# RA register map
Vendor: Renesas; Series: All Chips; File version: x.xx
Registers are 32-bit, read-write, reset 0x0 unless marked. A register's access mark holds for its fields unless they carry their own. Offsets are from the block's base; [hi:lo] are bit positions; lines under a group give offsets from that group; {n}, {i} and the like mark numbered series; 'fields as' and 'values as' point back to an identical list.

## R_ETHERC_EPTPC_COMMON — Ethernet PTP Controller Common
Base 0x40065000
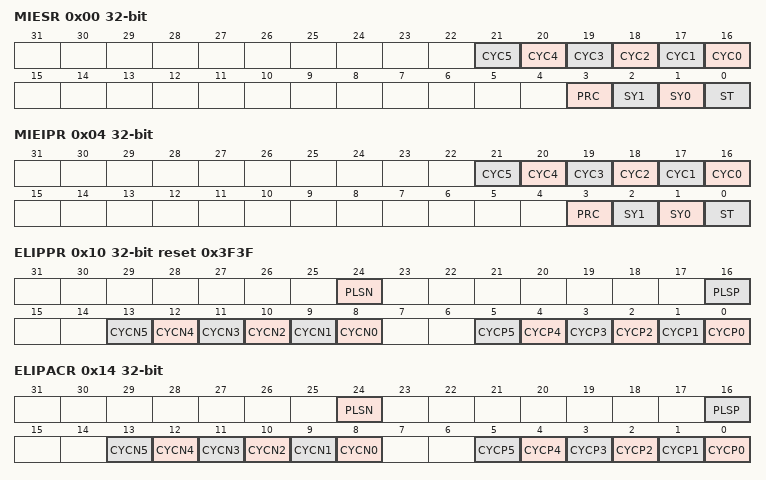
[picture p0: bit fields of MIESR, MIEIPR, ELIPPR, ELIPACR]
0x00 MIESR — MINT Interrupt Source Status Register
  [n+16] CYC{n} write-1-clears read-modifies (n=0..5) — Pulse Output Timer {n} Rising Edge Detection Flag
    0=A rising edge in the periodic pulse signal from pulse output timer {n} is not detected; 1=A rising edge in the periodic pulse signal from pulse output timer {n} is detected
  [3] PRC ro — PRC-TC Status Flag
    0=No change in the state of the PRC-TC module; 1=A change in the state of the PRC-TC module
  [2] SY1 ro — SYNFP1 Status Flag
    0=No change in the state of the SYNFP1 module; 1=A change in the state of the SYNFP1 module
  [1] SY0 ro — SYNFP0 Status Flag
    0=No change in the state of the SYNFP0 module; 1=A change in the state of the SYNFP0 module
  [0] ST ro — STCA Status Flag
    0=No change in the state of the STCA module; 1=A change in the state of the STCA module
0x04 MIEIPR — MINT Interrupt Request Permission Register
  [n+16] CYC{n} (n=0..5) — Pulse Output Timer {n} Rising Edge Detection Interrupt Request Permission
    0=Prohibits the generation of MINT interrupt requests in response to detection of a rising edge of pulse output timer {n}; 1=Permits the generation of MINT interrupt requests in response to detection of a rising edge of pulse output timer {n}
  [3] PRC — PRC-TC Status Interrupt Request Permission
    0=Prohibits the generation of MINT interrupt requests by the PRC-TC status flag; 1=Permits the generation of MINT interrupt requests by the PRCTC status flag
  [2] SY1 — SYNFP1 Status Interrupt Request Permission
    0=Prohibits the generation of MINT interrupt requests by the SYNFP1 status flag; 1=Permits the generation of MINT interrupt requests by the SYNFP1 status flag
  [1] SY0 — SYNFP0 Status Interrupt Request Permission
    0=Prohibits the generation of MINT interrupt requests by the SYNFP0 status flag; 1=Permits the generation of MINT interrupt requests by the SYNFP0 status flag
  [0] ST — STCA Status Interrupt Request Permission
    0=Prohibits the generation of MINT interrupt requests by the STCA status flag; 1=Permits the generation of MINT interrupt requests by the STCA status flag
0x10 ELIPPR reset 0x3F3F — ELC Output/ETHER_IPLS Interrupt Request Permission Register
  [24] PLSN — Pulse Output Timer Falling Edge Detection IPLS Interrupt Request Permission
    0=Prohibits IPLS interrupt requests due to falling edges of signals from the selected pulse output timer; 1=Permits IPLS interrupt requests due to falling edges of signals from the selected pulse output timer
  [16] PLSP — Pulse Output Timer Rising Edge Detection IPLS Interrupt Request Permission
    0=Prohibits IPLS interrupt requests due to rising edges of signals from the selected pulse output timer; 1=Permits IPLS interrupt requests due to rising edges of signals from the selected pulse output timer
  [n+8] CYCN{n} (n=0..5) — Pulse Output Timer {n} Falling Edge Detection Event Output Enable
    0=Falling edges of the signal from pulse output timer {n} are not conveyed to the ELC as event signals; 1=Falling edges of the signal from pulse output timer {n} are conveyed to the ELC as event signals
  [n] CYCP{n} (n=0..5) — Pulse Output Timer {n} Rising Edge Detection Event Output Enable
    0=Rising edges of the signal from pulse output timer {n} are not conveyed to the ELC as event signals; 1=Rising edges of the signal from pulse output timer {n} are conveyed to the ELC as event signals
0x14 ELIPACR — ELC Output/IPLS Interrupt Permission Automatic Clearing Register
  [24] PLSN — ELIPPR.PLSN Bit Automatic Clearing
    0=Disables automatic clearing of the enable bit for IPLS interrupt requests in response to detection of rising edges of the pulse output timer; 1=Enables automatic clearing of the enable bit for IPLS interrupt requests in response to detection of rising edges of the pulse output timer
  [16] PLSP — ELIPPR.PLSP Bit Automatic Clearing
    values as PLSN
  [n+8] CYCN{n} (n=0..5) — ELIPPR.CYCN{n} Bit Automatic Clearing
    0=Disables automatic clearing of the enable bit for the output of falling edges of pulse output timer {n}; 1=Enables automatic clearing of the enable bit for the output of falling edges of pulse output timer {n}
  [n] CYCP{n} (n=0..5) — ELIPPR.CYCP{n} Bit Automatic Clearing
    0=Disables automatic clearing of the enable bit for the output of rising edges of pulse output timer {n}; 1=Enables automatic clearing of the enable bit for the output of rising edges of pulse output timer {n}
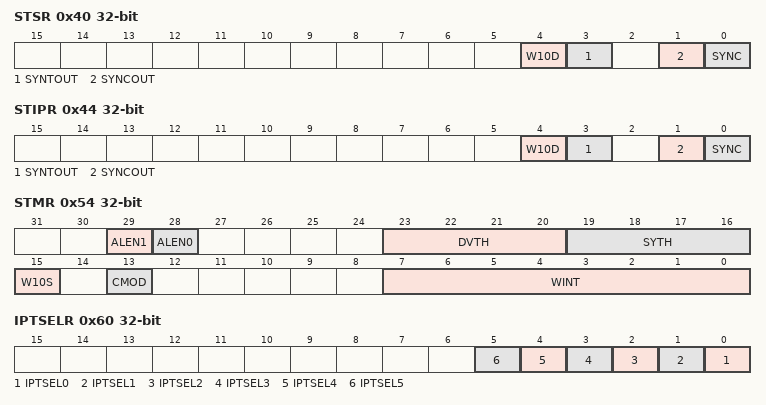
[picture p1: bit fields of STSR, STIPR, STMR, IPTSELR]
0x40 STSR — STCA Status Register
  [4] W10D write-1-clears — Worst 10 Acquisition Completion Flag
    0=Ten worst values not acquired yet; 1=Ten worst values acquired
  [3] SYNTOUT write-1-clears — Sync Message Reception Timeout Detection Flag
    0=Sync message reception timeout not detected; 1=Sync message reception timeout detected
  [1] SYNCOUT write-1-clears — Synchronization Loss Detection Flag
    0=Loss of synchronization not detected; 1=Loss of synchronization detected
  [0] SYNC write-1-clears — Synchronized State Detection Flag
    0=Synchronization not detected; 1=Synchronization detected
0x44 STIPR — STCA Status Notification Permission Register
  [4] W10D — W10D Status Notification Enable
    0=Disable notification of the STSR.W10D state; 1=Enable notification of the STSR.W10D state
  [3] SYNTOUT — SYNTOUT Status Notification Enable
    0=Disable notification of the STSR.SYNTOUT state; 1=Enable notification of the STSR.SYNTOUT state
  [1] SYNCOUT — SYNCOUT Status Notification Enable
    0=Disable notification of the STSR.SYNCOUT state; 1=Enable notification of the STSR.SYNCOUT state
  [0] SYNC — SYNC Status Notification Enable
    0=Disable notification of the STSR.SYNC state; 1=Enable notification of the STSR.SYNC state
0x50 STCFR — STCA Clock Frequency Setting Register
  [1:0] STCF — STCA Clock Frequency
    0=20MHz; 1=25MHz; 2=50MHz; 3=100 MHz
0x54 STMR — STCA Operating Mode Register
  [29] ALEN1 — Alarm Detection Enable 1
    0=The STSR.SYNTOUT flag is not set to 1 on detection of the Sync message reception timeout interrupt; 1=The STSR.SYNTOUT flag is not set to 1 on detection of the Sync message reception timeout interrupt
  [28] ALEN0 — Alarm Detection Enable 0
    0=The STSR.SYNC or SYNCOUT flag is not set to 1 on detection of synchronization or loss of synchronization; 1=The STSR.SYNC or SYNCOUT flag is set to 1 on detection of synchronization or loss of synchronization
  [23:20] DVTH — Synchronization Loss Detection Threshold Setting
    0=None; other=others ((DVTH) time)
  [19:16] SYTH — Synchronized State Detection Threshold Setting
    0=None; other=others ((SYTH) time)
  [15] W10S — Worst 10 Acquisition Control Select
    0=Measurement is started by hardware and the value acquired in the PW10VR or MW10R register is used as the limit for filtering; 1=Measurement is started by the GETW10R.GW10 bit. Also, the value set in the PLIMITR or MLIMITR register is used as the limit for filtering.
  [13] CMOD — Time Synchronization Correction Mode
    0=Mode 1; 1=Mode 2
  [7:0] WINT — Worst 10 Acquisition Time
    0=The worst 10 values are not acquired; other=others (Sync message reception: (WINT) time)
0x58 SYNTOR — Sync Message Reception Timeout Register
  [31:0] SYNTOR — A Sync message not being received within 1024 x n (ns), where n is the setting, leads to a timeout for reception of Sync messages, leading to the STSR.SYNTOUT flag being set to 1.
0x60 IPTSELR — IPLS Interrupt Request Timer Select Register
  [n] IPTSEL{n} (n=0..5) — Pulse Output Timer {n} Select
    0=Pulse output timer {n} is not selected as a source of IPLS interrupt requests; 1=Pulse output timer {n} is selected as a source of IPLS interrupt requests
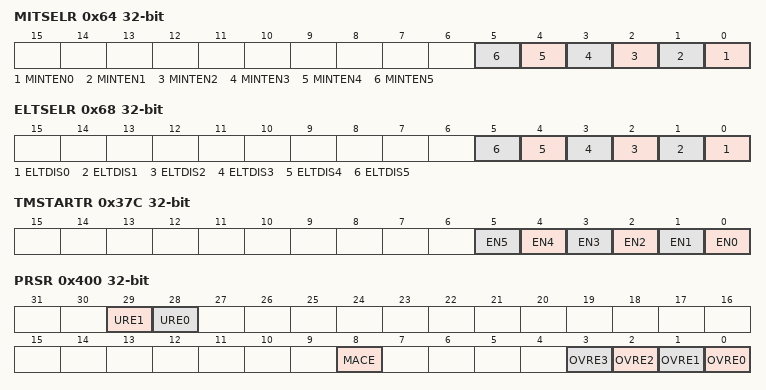
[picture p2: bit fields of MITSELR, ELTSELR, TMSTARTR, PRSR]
0x64 MITSELR — MINT Interrupt Request Timer Select Register
  [n] MINTEN{n} (n=0..5) — Pulse Output Timer {n} MINT Interrupt Output Enable
    0=Output of rising edges by pulse output timer {n} is not reflected by the MIESR.CYC{n} flag as a MINT interrupt source; 1=Output of rising edges by pulse output timer {n} is reflected by the MIESR.CYC{n} flag as a MINT interrupt source
0x68 ELTSELR — ELC Output Timer Select Register
  [n] ELTDIS{n} (n=0..5) — Pulse Output Timer {n} Event Generation Disable
    0=Pulse output timer {n} is used for the generation of event signals for the ELC; 1=Pulse output timer {n} is not used for the generation of event signals for the ELC
0x6C STCHSELR — Time Synchronization Channel Select Register
  [0] SYSEL — Timer Information Input SelectNOTE: Do not change the value of this bit while the SYNSTARTR.STR bit is 1.
    0=Time information from synchronization from the SYNFP0 module is used; 1=Time information from synchronization from the SYNFP1 module is used
0x80 SYNSTARTR — Slave Time Synchronization Start Register
  [0] STR — Slave Time Synchronization Control
    0=Slave time synchronization is stopped; 1=Slave time synchronization is started
0x84 LCIVLDR wo — Local Time Counter Initial Value Load Directive Register
  [0] LOAD — Local Time Counter Initial Value Load Directive
    0=The initial value is not loaded into the local time counter; 1=The initial value is loaded into the local time counter
0x90 SYNTDARU — Synchronization Loss Detection Threshold Registers
  [31:0] SYNTDARU — These bits hold the setting for the higher-order 32 bits of the threshold for detection of loss of synchronization.
0x94 SYNTDARL — Synchronization Loss Detection Threshold Registers
  [31:0] SYNTDARL — These bits hold the setting for the lower-order 32 bits of the threshold for detection of loss of synchronization.
0x98 SYNTDBRU — Synchronization Detection Threshold Registers
  [31:0] SYNTDBRU — These bits hold the setting for the higher-order 32 bits of the threshold for detection of synchronization.
0x9C SYNTDBRL — Synchronization Detection Threshold Registers
  [31:0] SYNTDBRL — These bits hold the setting for the lower-order 32 bits of the threshold for detection of synchronization.
0xB0 LCIVRU — Local Time Counter Initial Value Registers
  [15:0] LCIVRU — These bits hold the setting for the higher-order 16 bits of the integer portion of the initial value for the local timer counter.
0xB4 LCIVRM — Local Time Counter Initial Value Registers
  [31:0] LCIVRM — These bits hold the setting for the lower-order 32 bits of the integer portion of the initial value for the local timer counter.
0xB8 LCIVRL — Local Time Counter Initial Value Registers
  [31:0] LCIVRL — These bits hold the setting for the fractional portion of the initial value of the local timer counter in nanoseconds.
0x124 GETW10R — Worst 10 Acquisition Directive Register
  [0] GW10 — Worst 10 Acquisition Directive
    0=The worst-10 values are not acquired; 1=Starts acquisition of the worst-10 values
0x128 PLIMITRU — Positive Gradient Limit Registers
  [30:0] PLIMITRU — These bits hold the setting for the higher-order 31 bits of the limit for the positive gradient.
0x12C PLIMITRM — Positive Gradient Limit Registers
  [31:0] PLIMITRM — These bits hold the setting for the middle-order 32 bits of the limit for the positive gradient.
0x130 PLIMITRL — Positive Gradient Limit Registers
  [31:0] PLIMITRL — These bits hold the setting for the lower-order 32 bits of the limit for the positive gradient.
0x134 MLIMITRU — Negative Gradient Limit Registers
  [30:0] MLIMITRU — These bits hold the setting for the higher-order 31 bits of the limit for the negative gradient.
0x138 MLIMITRM — Negative Gradient Limit Registers
  [31:0] MLIMITRM — These bits hold the setting for the middle-order 32 bits of the limit for the negative gradient.
0x13C MLIMITRL — Negative Gradient Limit Registers
  [31:0] MLIMITRL — These bits hold the setting for the lower-order 32 bits of the limit for the negative gradient.
0x140 GETINFOR — Statistical Information Retention Control Register
  [0] INFO — Information Retention ControlNOTE: Once information fetching is directed, values of various statistical information read before completion of information fetching are not guaranteed.
    0=Has no effects.(write) / Information retention is completed.(read); 1=Information is retained.(write) / Processing for information retention is in progress.(read)
0x170 LCCVRU ro — Local Time Counters
  [15:0] LCCVRU — These bits are for reading the higher-order 16 bits of the integer portion of the local timer counter's value.
0x174 LCCVRM ro — Local Time Counters
  [31:0] LCCVRM — These bits are for reading the lower-order 32 bits of the integer portion of the local timer counter's value.
0x178 LCCVRL ro — Local Time Counters
  [31:0] LCCVRL — These bits are for reading the fractional portion of the local timer counter's value (in nanoseconds).
0x210 PW10VRU ro — Positive Gradient Worst 10 Value Registers
  [31:0] PW10VRU — These bits are for reading the higher-order 32 bits of the positive gradient value.
0x214 PW10VRM ro — Positive Gradient Worst 10 Value Registers
  [31:0] PW10VRM — These bits are for reading the middle-order 32 bits of the positive gradient value.
0x218 PW10VRL ro — Positive Gradient Worst 10 Value Registers
  [31:0] PW10VRL — These bits are for reading the lower-order 32 bits of the positive gradient value.
0x2D0 MW10RU ro — Negative Gradient Worst 10 Value Registers
  [31:0] MW10RU — These bits are for reading the higher-order 32 bits of the negative gradient value.
0x2D4 MW10RM ro — Negative Gradient Worst 10 Value Registers
  [31:0] MW10RM — These bits are for reading the middle-order 32 bits of the negative gradient value.
0x2D8 MW10RL ro — Negative Gradient Worst 10 Value Registers
  [31:0] MW10RL — These bits are for reading the lower-order 32 bits of the negative gradient value.
{0x300+0x10*i} TM[{i}] (i=0..5) group — Timer Setting Registers
  0x00 STTRU — Timer Start Time Setting Register
    [31:0] TMSTTRU — These bits hold the setting for the higher-order 32 bits of the start time of the pulse output timer in nanoseconds.
  0x04 STTRL — Timer Start Time Setting Register
    [31:0] TMSTTRL — These bits hold the setting for the lower-order 32 bits of the start time of the pulse output timer in nanoseconds.
  0x08 CYCR — Timer Cycle Setting Registers
    [29:0] TMCYCR — These bits set the cycle of the pulse output timer in nanoseconds. Set a value that is equivalent to at least four cycles of the STCA clock.
  0x0C PLSR — Timer Pulse Width Setting Register
    [28:0] TMPLSR — These bits set the width at high level of the pulse signal from the timer in nanoseconds. Set a value that is equivalent to at least two cycles of the STCA clock.
0x37C TMSTARTR — Timer Start Register
  [n] EN{n} (n=0..5) — Pulse Output Timer {n} Start
    0=Stops pulse output timer {n}; 1=Starts pulse output timer {n}
0x400 PRSR — PRC-TC Status Register
  [29] URE1 write-1-clears — Relay Packet Underflow Detection Flag 1
    0=No underflow in transfer of data from SYNFP0 to SYNFP1; 1=An underflow has been detected in transfer of data from SYNFP0 to SYNFP1
  [28] URE0 write-1-clears — Relay Packet Underflow Detection Flag 0
    0=No underflow in transfer of data from SYNFP1 to SYNFP0; 1=An underflow has been detected in transfer of data from SYNFP1 to SYNFP0
  [8] MACE write-1-clears read-modifies — Originating MAC Address Mismatch Detection Flag
    0=A MAC address mismatch has not been detected; 1=A MAC address mismatch has been detected
  [3] OVRE3 write-1-clears read-modifies — Relay Packet Overflow Detection Flag 3
    0=No overflow in transfer of data from SYNFP0 to SYNFP1; 1=An overflow has been detected in transfer of data from SYNFP0 to SYNFP1
  [2] OVRE2 write-1-clears read-modifies — Relay Packet Overflow Detection Flag 2
    0=No overflow in transfer of data from SYNFP1 to SYNFP0; 1=An overflow has been detected in transfer of data from SYNFP1 to SYNFP0
  [1] OVRE1 write-1-clears read-modifies — Relay Packet Overflow Detection Flag 1
    0=No overflow in transfer of data from SYNFP0 to PTPEDMAC; 1=An overflow has been detected in transfer of data from SYNFP0 to PTPEDMAC
  [0] OVRE0 write-1-clears read-modifies — Relay Packet Overflow Detection Flag 0
    0=No overflow in transfer of data from SYNFP1 to PTPEDMAC; 1=An overflow has been detected in transfer of data from SYNFP1 to PTPEDMAC
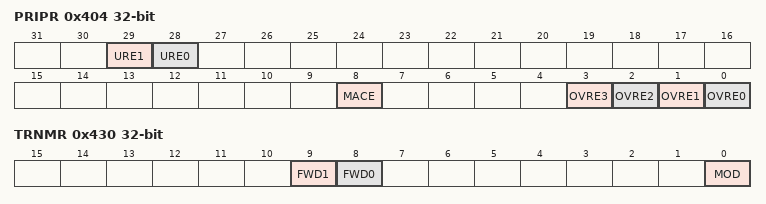
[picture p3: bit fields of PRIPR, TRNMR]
0x404 PRIPR — PRC-TC Status Notification Permission Register
  [29] URE1 — PRSR.URE1 Status Notification Permission
    0=Prohibits notification of the state of PRSR.URE1; 1=Permits notification of the state of PRSR.URE1
  [28] URE0 — PRSR.URE0 Status Notification Permission
    0=Prohibits notification of the state of PRSR.URE0; 1=Permits notification of the state of PRSR.URE0
  [8] MACE — PRSR.MACE Status Notification Permission
    0=Prohibits notification of the state of PRSR.MACE; 1=Permits notification of the state of PRSR.MACE
  [n] OVRE{n} (n=0..3) — PRSR.OVRE{n} Status Notification Permission
    0=Prohibits notification of the state of PRSR.OVRE{n}; 1=Permits notification of the state of PRSR.OVRE{n}
{0x410+8i} PR[{i}] (i=0..1) group — Local MAC Address Registers
  0x00 MACRU — Channel Local MAC Address Register
    [23:0] PRMACRU — These bits hold the setting for the higher-order 24 bits of the local MAC address for Ethernet port 0.
  0x04 MACRL — Channel Local MAC Address Register
    [23:0] PRMACRL — These bits hold the setting for the higher-order 24 bits of the local MAC address for Ethernet port 0.
0x420 TRNDISR — Packet Transmission Control Register
  [1:0] TDIS — Packet Transmission Control
    0=PTP packets are transmitted through both Ethernet port 0 and Ethernet port 1; 1=PTP packets are only transmitted through Ethernet port 0; 2=PTP packets are only transmitted through Ethernet port 1; 3=Setting prohibited
0x430 TRNMR — Relay Mode Register
  [9] FWD1 — Channel 1 Relay Enable
    0=Unicast, multicast (other than PTP packets), and broadcast messages from the other node are not relayed from port 1 to port 0; 1=Unicast, multicast (other than PTP packets), and broadcast messages from the other node are relayed from port 1 to port 0
  [8] FWD0 — Channel 0 Relay Enable
    0=Unicast, multicast (other than PTP packets), and broadcast messages from the other node are not relayed from port 0 to port 1; 1=Unicast, multicast (other than PTP packets), and broadcast messages from the other node are relayed from port 0 to port 1
  [0] MOD — Cut-Through Mode
    0=Store-and-forward; 1=Cut-through
0x434 TRNCTTDR reset 0x60 — Cut-Through Transfer Start Threshold Register
  [10:0] THVAL — FIFO Read Start ThresholdThreshold for starting to read data from the relay FIFO in cut-through mode (specified as the number of bytes)NOTE1: A value cannot be set in the lower-order 2 bits. These bits are fixed to 0.NOTE2: A value of less than 96 bytes cannot be set.
